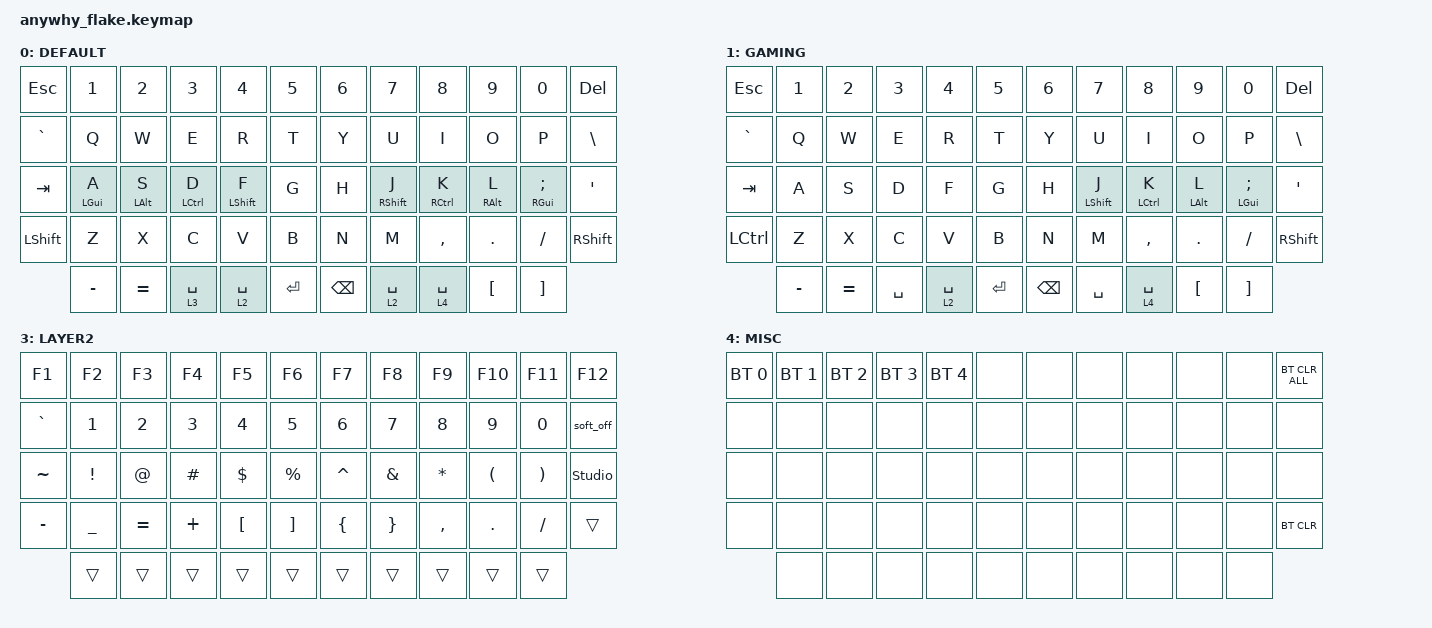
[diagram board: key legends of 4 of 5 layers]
#include <behaviors.dtsi>
#include <dt-bindings/zmk/bt.h>
#include <dt-bindings/zmk/keys.h>
#include <dt-bindings/zmk/pointing.h>

#define U_MOUSE_MOVE_MAX 900

#undef MOVE_UP
#undef MOVE_DOWN
#undef MOVE_LEFT
#undef MOVE_RIGHT

#define MOVE_UP MOVE_Y(-U_MOUSE_MOVE_MAX)
#define MOVE_DOWN MOVE_Y(U_MOUSE_MOVE_MAX)
#define MOVE_LEFT MOVE_X(-U_MOUSE_MOVE_MAX)
#define MOVE_RIGHT MOVE_X(U_MOUSE_MOVE_MAX)
#define U_MOUSE_SCROLL_MAX 20

#undef SCRL_UP
#undef SCRL_DOWN
#undef SCRL_LEFT
#undef SCRL_RIGHT

#define SCRL_UP MOVE_Y(U_MOUSE_SCROLL_MAX)
#define SCRL_DOWN MOVE_Y(-U_MOUSE_SCROLL_MAX)
#define SCRL_LEFT MOVE_X(-U_MOUSE_SCROLL_MAX)
#define SCRL_RIGHT MOVE_X(U_MOUSE_SCROLL_MAX)

&mmv {
    time-to-max-speed-ms = <700>;
    acceleration-exponent = <1>;
};

&msc {
    time-to-max-speed-ms = <500>;
    acceleration-exponent = <0>;
};

/ {
    combos {
        compatible = "zmk,combos";

        enter_gaming {
            bindings = <&to 1>;
            key-positions = <15 13 14 16 17>;
        };

        leave_gaming {
            bindings = <&to 0>;
            key-positions = <20 19 21 22 18>;
        };

        capslock {
            bindings = <&kp CAPSLOCK>;
            key-positions = <36 47>;
        };
    };

    macros {
        bt_clr_0: bt_clr_0 {
            compatible = "zmk,behavior-macro";
            #binding-cells = <0>;
            bindings = <&bt BT_SEL 0 &bt BT_CLR>;
            label = "BT_CLR_0";
        };

        bt_clr_1: bt_clr_1 {
            compatible = "zmk,behavior-macro";
            #binding-cells = <0>;
            bindings = <&bt BT_SEL 1 &bt BT_CLR>;
            label = "BT_CLR_1";
        };

        bt_clr_2: bt_clr_2 {
            compatible = "zmk,behavior-macro";
            #binding-cells = <0>;
            bindings = <&bt BT_SEL 2 &bt BT_CLR>;
            label = "BT_CLR_2";
        };

        bt_clr_3: bt_clr_3 {
            compatible = "zmk,behavior-macro";
            #binding-cells = <0>;
            bindings = <&bt BT_SEL 3 &bt BT_CLR>;
            label = "BT_CLR_3";
        };

        bt_clr_4: bt_clr_4 {
            compatible = "zmk,behavior-macro";
            #binding-cells = <0>;
            bindings = <&bt BT_SEL 4 &bt BT_CLR>;
            label = "BT_CLR_4";
        };
    };

    behaviors {
        bhm: balanced_homerow_mods {
            compatible = "zmk,behavior-hold-tap";
            label = "HOMEROW_MODS";
            bindings = <&kp>, <&kp>;

            #binding-cells = <2>;
            tapping-term-ms = <250>;
            quick-tap-ms = <0>;
            flavor = "balanced";
        };
    };

    keymap {
        compatible = "zmk,keymap";

        DEFAULT {
            bindings = <
&kp ESC         &kp N1           &kp N2           &kp N3        &kp N4        &kp N5       &kp N6         &kp N7         &kp N8        &kp N9            &kp N0               &kp DELETE
&kp GRAVE       &kp Q            &kp W            &kp E         &kp R         &kp T        &kp Y          &kp U          &kp I         &kp O             &kp P                &kp BACKSLASH
&kp TAB         &bhm LEFT_GUI A  &bhm LEFT_ALT S  &bhm LCTRL D  &bhm LSHFT F  &kp G        &kp H          &bhm RSHIFT J  &bhm RCTRL K  &bhm RIGHT_ALT L  &bhm RIGHT_GUI SEMI  &kp APOS
&kp LEFT_SHIFT  &kp Z            &kp X            &kp C         &kp V         &kp B        &kp N          &kp M          &kp COMMA     &kp DOT           &kp FSLH             &kp RIGHT_SHIFT
                &kp MINUS        &kp EQUAL        &lt 3 SPACE   &lt 2 SPACE   &kp ENTER    &kp BACKSPACE  &lt 2 SPACE    &lt 4 SPACE   &kp LEFT_BRACKET  &kp RIGHT_BRACKET
            >;
        };

        GAMING {
            bindings = <
&kp ESC    &kp N1     &kp N2     &kp N3     &kp N4       &kp N5       &kp N6         &kp N7             &kp N8               &kp N9            &kp N0               &kp DELETE
&kp GRAVE  &kp Q      &kp W      &kp E      &kp R        &kp T        &kp Y          &kp U              &kp I                &kp O             &kp P                &kp BACKSLASH
&kp TAB    &kp A      &kp S      &kp D      &kp F        &kp G        &kp H          &bhm LEFT_SHIFT J  &bhm LEFT_CONTROL K  &bhm LEFT_ALT L   &bhm LGUI SEMICOLON  &kp APOS
&kp LCTRL  &kp Z      &kp X      &kp C      &kp V        &kp B        &kp N          &kp M              &kp COMMA            &kp DOT           &kp FSLH             &kp RIGHT_SHIFT
           &kp MINUS  &kp EQUAL  &kp SPACE  &lt 2 SPACE  &kp ENTER    &kp BACKSPACE  &kp SPACE          &lt 4 SPACE          &kp LEFT_BRACKET  &kp RIGHT_BRACKET
            >;
        };

        LAYER1 {
            bindings = <
&kp F1  &kp F2  &kp F3          &kp F4    &kp F5           &kp F6            &kp F7          &kp F8          &kp F9          &kp F10          &kp F11  &kp F12
&none   &none   &mkp LCLK       &kp UP    &mkp RCLK        &msc SCRL_UP      &msc SCRL_UP    &mkp LCLK       &mmv MOVE_UP    &mkp RCLK        &none    &none
&none   &none   &kp LEFT        &kp DOWN  &kp RIGHT        &msc SCRL_DOWN    &msc SCRL_DOWN  &mmv MOVE_LEFT  &mmv MOVE_DOWN  &mmv MOVE_RIGHT  &none    &none
&none   &none   &msc SCRL_LEFT  &none     &msc SCRL_RIGHT  &none             &mkp MCLK       &mkp MB4        &mkp MB5        &none            &none    &none
        &trans  &trans          &trans    &trans           &none             &none           &trans          &trans          &trans
            >;
        };

        LAYER2 {
            bindings = <
&kp F1     &kp F2           &kp F3       &kp F4    &kp F5            &kp F6               &kp F7          &kp F8           &kp F9        &kp F10               &kp F11                &kp F12
&kp GRAVE  &kp N1           &kp N2       &kp N3    &kp N4            &kp N5               &kp N6          &kp N7           &kp N8        &kp N9                &kp N0                 &soft_off
&kp TILDE  &kp EXCLAMATION  &kp AT_SIGN  &kp HASH  &kp DOLLAR        &kp PERCENT          &kp CARET       &kp AMPERSAND    &kp ASTERISK  &kp LEFT_PARENTHESIS  &kp RIGHT_PARENTHESIS  &studio_unlock
&kp MINUS  &kp UNDERSCORE   &kp EQUAL    &kp PLUS  &kp LEFT_BRACKET  &kp RIGHT_BRACKET    &kp LEFT_BRACE  &kp RIGHT_BRACE  &kp COMMA     &kp DOT               &kp FSLH               &trans
           &trans           &trans       &trans    &trans            &trans               &trans          &trans           &trans        &trans                &trans
            >;
        };

        MISC {
            bindings = <
&bt BT_SEL 0  &bt BT_SEL 1  &bt BT_SEL 2  &bt BT_SEL 3  &bt BT_SEL 4  &none    &none  &none  &none  &none  &none  &bt BT_CLR_ALL
&none         &none         &none         &none         &none         &none    &none  &none  &none  &none  &none  &none
&none         &none         &none         &none         &none         &none    &none  &none  &none  &none  &none  &none
&none         &none         &none         &none         &none         &none    &none  &none  &none  &none  &none  &bt BT_CLR
              &none         &none         &none         &none         &none    &none  &none  &none  &none  &none
            >;
        };
    };
};

&lt {
    flavor = "tap-preferred";
    tapping-term-ms = <125>;
    require-prior-idle-ms = <150>;
};
